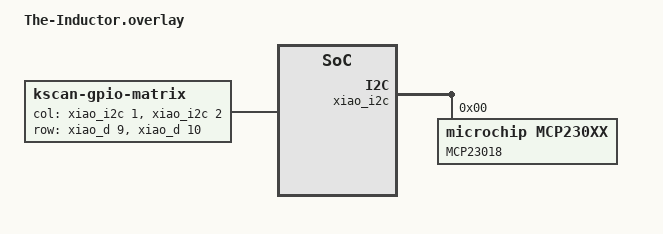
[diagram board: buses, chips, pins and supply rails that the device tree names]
&xiao_i2c {
    status = "okay";

    expander: mcp230xx@0 {
        compatible = "microchip,mcp230xx";
        gpio-controller;
        #gpio-cells = <2>;
        ngpios = <16>;
        status = "okay";
        reg = <0>;    
        label = "MCP23018";
    };

};

/ {
    chosen {
        zmk,kscan = &kscan;
    };

    kscan: kscan {
        compatible = "zmk,kscan-gpio-matrix";
        label = "KSCAN";

        diode-direction = "col2row";

        col-gpios
            = <&xiao_i2c 1 (GPIO_ACTIVE_HIGH)>
            , <&xiao_i2c 2 (GPIO_ACTIVE_HIGH)>
            ;

        row-gpios
            = <&xiao_d 9 (GPIO_ACTIVE_HIGH | GPIO_PULL_DOWN)>
            , <&xiao_d 10 (GPIO_ACTIVE_HIGH | GPIO_PULL_DOWN)>
            ;
    };
};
